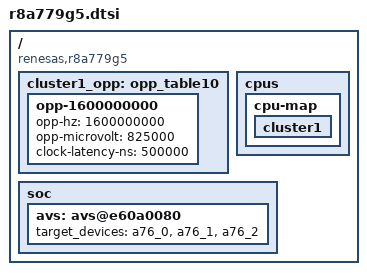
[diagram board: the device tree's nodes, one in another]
// SPDX-License-Identifier: (GPL-2.0-only OR BSD-2-Clause)
/*
 * Device Tree Source for the R-Car V4H (R8A779G5) SoC
 *
 * Copyright (C) 2024 Renesas Electronics Corp.
 */

#include <dt-bindings/clock/r8a779g0-cpg-mssr.h>
#include <dt-bindings/interrupt-controller/arm-gic.h>
#include <dt-bindings/power/r8a779g0-sysc.h>
#include <dt-bindings/ipmmu/rcar-ipmmu.h>

/ {
	compatible = "renesas,r8a779g5", "renesas,r8a779g0";

	cluster1_opp: opp_table10 {
		opp-1600000000 {
			opp-hz = /bits/ 64 <1600000000>;
			opp-microvolt = <825000>;
			clock-latency-ns = <500000>;
		};

		/delete-node/opp-1700000000;
		/delete-node/opp-1800000000;
	};

	cpus {
		cpu-map {
			cluster1 {
				/delete-node/core1;
			};
		};

		/delete-node/cpu@10100;
	};

	soc: soc {
		avs: avs@e60a0080 {
			target_devices = <&a76_0>, <&a76_1>, <&a76_2>;
		};
	};
};
